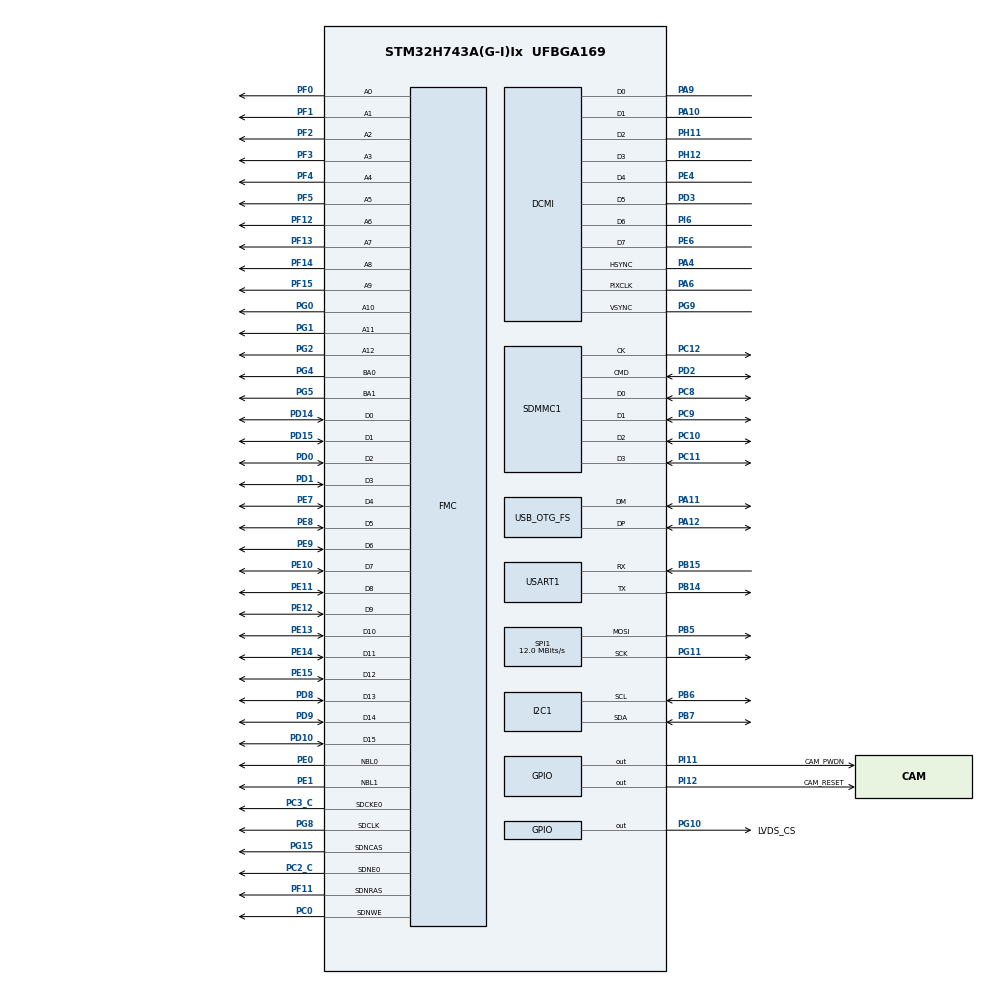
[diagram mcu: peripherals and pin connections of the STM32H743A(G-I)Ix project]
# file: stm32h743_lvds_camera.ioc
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CORTEX_M7.default_mode_Activation=1
DCMI.JPEGMode=DCMI_JPEG_ENABLE
DCMI.PCKPolarity=DCMI_PCKPOLARITY_RISING
DCMI.VSPolarity=DCMI_VSPOLARITY_HIGH
Dma.DCMI.0.Direction=DMA_PERIPH_TO_MEMORY
Dma.DCMI.0.EventEnable=DISABLE
Dma.DCMI.0.FIFOMode=DMA_FIFOMODE_ENABLE
Dma.DCMI.0.FIFOThreshold=DMA_FIFO_THRESHOLD_FULL
Dma.DCMI.0.Instance=DMA1_Stream0
Dma.DCMI.0.MemBurst=DMA_MBURST_SINGLE
Dma.DCMI.0.MemDataAlignment=DMA_MDATAALIGN_WORD
Dma.DCMI.0.MemInc=DMA_MINC_ENABLE
Dma.DCMI.0.Mode=DMA_NORMAL
Dma.DCMI.0.PeriphBurst=DMA_PBURST_SINGLE
Dma.DCMI.0.PeriphDataAlignment=DMA_PDATAALIGN_WORD
Dma.DCMI.0.PeriphInc=DMA_PINC_DISABLE
Dma.DCMI.0.Polarity=HAL_DMAMUX_REQ_GEN_RISING
Dma.DCMI.0.Priority=DMA_PRIORITY_VERY_HIGH
Dma.DCMI.0.RequestNumber=1
Dma.DCMI.0.SignalID=NONE
Dma.DCMI.0.SyncEnable=DISABLE
Dma.DCMI.0.SyncPolarity=HAL_DMAMUX_SYNC_NO_EVENT
Dma.DCMI.0.SyncRequestNumber=1
Dma.DCMI.0.SyncSignalID=NONE
Dma.Request0=DCMI
FMC.CASLatency1=FMC_SDRAM_CAS_LATENCY_3
FMC.ColumnBitsNumber1=FMC_SDRAM_COLUMN_BITS_NUM_9
FMC.ExitSelfRefreshDelay1=8
FMC.LoadToActiveDelay1=2
FMC.RCDDelay1=3
FMC.RPDelay1=3
FMC.RPDelay2=3
FMC.ReadBurst1=FMC_SDRAM_RBURST_ENABLE
FMC.ReadBurst2=FMC_SDRAM_RBURST_ENABLE
FMC.ReadPipeDelay1=FMC_SDRAM_RPIPE_DELAY_1
FMC.ReadPipeDelay2=FMC_SDRAM_RPIPE_DELAY_1
FMC.RowCycleDelay1=7
FMC.RowCycleDelay2=7
FMC.SDClockPeriod1=FMC_SDRAM_CLOCK_PERIOD_2
FMC.SDClockPeriod2=FMC_SDRAM_CLOCK_PERIOD_2
FMC.SelfRefreshTime1=5
FMC.WriteRecoveryTime1=2
I2C1.Timing=0x307075B1
Mcu.Family=STM32H7
Mcu.Name=STM32H743A(G-I)Ix
Mcu.Package=UFBGA169
NVIC.DCMI_IRQn=true\:0\:0\:false\:false\:true\:true\:true\:true
NVIC.DMA1_Stream0_IRQn=true\:0\:0\:false\:false\:true\:false\:true\:true
NVIC.PriorityGroup=NVIC_PRIORITYGROUP_4
PA10.GPIO_Speed=GPIO_SPEED_FREQ_VERY_HIGH
PA10.Mode=Slave_8_bits_External_Synchro
PA10.Signal=DCMI_D1
PA11.Mode=Device_Only
PA11.Signal=USB_OTG_FS_DM
PA12.Mode=Device_Only
PA12.Signal=USB_OTG_FS_DP
PA4.Mode=Slave_8_bits_External_Synchro
PA4.Signal=DCMI_HSYNC
PA6.GPIO_Speed=GPIO_SPEED_FREQ_VERY_HIGH
PA6.Mode=Slave_8_bits_External_Synchro
PA6.Signal=DCMI_PIXCLK
PA9.GPIO_Speed=GPIO_SPEED_FREQ_VERY_HIGH
PA9.Mode=Slave_8_bits_External_Synchro
PA9.Signal=DCMI_D0
PB14.Mode=Asynchronous
PB14.Signal=USART1_TX
PB15.Mode=Asynchronous
PB15.Signal=USART1_RX
PB5.Mode=TX_Only_Simplex_Unidirect_Master
PB5.Signal=SPI1_MOSI
PB6.Mode=I2C
PB6.Signal=I2C1_SCL
PB7.Mode=I2C
PB7.Signal=I2C1_SDA
PC0.Signal=FMC_SDNWE
PC10.Mode=SD_4_bits_Wide_bus
PC10.Signal=SDMMC1_D2
PC11.Mode=SD_4_bits_Wide_bus
PC11.Signal=SDMMC1_D3
PC12.Mode=SD_4_bits_Wide_bus
PC12.Signal=SDMMC1_CK
PC2_C.Mode=SdramChipSelect1_1
PC2_C.Signal=FMC_SDNE0
PC3_C.Mode=SdramChipSelect1_1
PC3_C.Signal=FMC_SDCKE0
PC8.Mode=SD_4_bits_Wide_bus
PC8.Signal=SDMMC1_D0
PC9.Mode=SD_4_bits_Wide_bus
PC9.Signal=SDMMC1_D1
PD0.Signal=FMC_D2_DA2
PD1.Signal=FMC_D3_DA3
PD10.Signal=FMC_D15_DA15
PD14.Signal=FMC_D0_DA0
PD15.Signal=FMC_D1_DA1
PD2.Mode=SD_4_bits_Wide_bus
PD2.Signal=SDMMC1_CMD
PD3.GPIO_Speed=GPIO_SPEED_FREQ_VERY_HIGH
PD3.Mode=Slave_8_bits_External_Synchro
PD3.Signal=DCMI_D5
PD8.Signal=FMC_D13_DA13
PD9.Signal=FMC_D14_DA14
PE0.Signal=FMC_NBL0
PE1.Signal=FMC_NBL1
PE10.Signal=FMC_D7_DA7
PE11.Signal=FMC_D8_DA8
PE12.Signal=FMC_D9_DA9
PE13.Signal=FMC_D10_DA10
PE14.Signal=FMC_D11_DA11
PE15.Signal=FMC_D12_DA12
PE4.GPIO_Speed=GPIO_SPEED_FREQ_VERY_HIGH
PE4.Mode=Slave_8_bits_External_Synchro
PE4.Signal=DCMI_D4
PE6.GPIO_Speed=GPIO_SPEED_FREQ_VERY_HIGH
PE6.Mode=Slave_8_bits_External_Synchro
PE6.Signal=DCMI_D7
PE7.Signal=FMC_D4_DA4
PE8.Signal=FMC_D5_DA5
PE9.Signal=FMC_D6_DA6
PF0.Signal=FMC_A0
PF1.Signal=FMC_A1
PF11.Signal=FMC_SDNRAS
PF12.Signal=FMC_A6
PF13.Signal=FMC_A7
PF14.Signal=FMC_A8
PF15.Signal=FMC_A9
PF2.Signal=FMC_A2
PF3.Signal=FMC_A3
PF4.Signal=FMC_A4
PF5.Signal=FMC_A5
PG0.Signal=FMC_A10
PG1.Signal=FMC_A11
PG10.GPIO_Label=LVDS_CS
PG10.GPIO_Speed=GPIO_SPEED_FREQ_VERY_HIGH
PG10.PinState=GPIO_PIN_SET
PG10.Signal=GPIO_Output
PG11.Mode=TX_Only_Simplex_Unidirect_Master
PG11.Signal=SPI1_SCK
PG15.Signal=FMC_SDNCAS
PG2.Signal=FMC_A12
PG4.Signal=FMC_A14_BA0
PG5.Signal=FMC_A15_BA1
PG8.Signal=FMC_SDCLK
PG9.Mode=Slave_8_bits_External_Synchro
PG9.Signal=DCMI_VSYNC
PH0-OSC_IN\ (PH0).Mode=HSE-External-Oscillator
PH0-OSC_IN\ (PH0).Signal=RCC_OSC_IN
PH1-OSC_OUT\ (PH1).Mode=HSE-External-Oscillator
PH1-OSC_OUT\ (PH1).Signal=RCC_OSC_OUT
PH11.GPIO_Speed=GPIO_SPEED_FREQ_VERY_HIGH
PH11.Mode=Slave_8_bits_External_Synchro
PH11.Signal=DCMI_D2
PH12.GPIO_Speed=GPIO_SPEED_FREQ_VERY_HIGH
PH12.Mode=Slave_8_bits_External_Synchro
PH12.Signal=DCMI_D3
PI11.GPIO_Label=CAM_PWDN
PI11.Signal=GPIO_Output
PI12.GPIO_Label=CAM_RESET
PI12.PinState=GPIO_PIN_SET
PI12.Signal=GPIO_Output
PI6.GPIO_Speed=GPIO_SPEED_FREQ_VERY_HIGH
PI6.Mode=Slave_8_bits_External_Synchro
PI6.Signal=DCMI_D6
ProjectManager.HeapSize=0x200
ProjectManager.StackSize=0x400
ProjectManager.TargetToolchain=MDK-ARM V5.32
RCC.ADCFreq_Value=50390625
RCC.APB1Freq_Value=120000000
RCC.APB2Freq_Value=120000000
RCC.APB3Freq_Value=120000000
RCC.APB4Freq_Value=120000000
RCC.CortexFreq_Value=240000000
RCC.DIVM1=5
RCC.DIVN1=96
RCC.DIVQ1=5
RCC.HCLKFreq_Value=120000000
RCC.HPRE=RCC_HCLK_DIV2
RCC.PLLFRACN=0
RCC.PLLSourceVirtual=RCC_PLLSOURCE_HSE
RCC.SYSCLKFreq_VALUE=240000000
RCC.SYSCLKSource=RCC_SYSCLKSOURCE_PLLCLK
RCC.USBCLockSelection=RCC_USBCLKSOURCE_HSI48
RCC.USBFreq_Value=48000000
SDMMC1.HardwareFlowControl=SDMMC_HARDWARE_FLOW_CONTROL_ENABLE
SH.FMC_A0.0=FMC_A0,13b-sda1
SH.FMC_A1.0=FMC_A1,13b-sda1
SH.FMC_A10.0=FMC_A10,13b-sda1
SH.FMC_A11.0=FMC_A11,13b-sda1
SH.FMC_A12.0=FMC_A12,13b-sda1
SH.FMC_A14_BA0.0=FMC_BA0,FourSdramBanks1
SH.FMC_A15_BA1.0=FMC_BA1,FourSdramBanks1
SH.FMC_A2.0=FMC_A2,13b-sda1
SH.FMC_A3.0=FMC_A3,13b-sda1
SH.FMC_A4.0=FMC_A4,13b-sda1
SH.FMC_A5.0=FMC_A5,13b-sda1
SH.FMC_A6.0=FMC_A6,13b-sda1
SH.FMC_A7.0=FMC_A7,13b-sda1
SH.FMC_A8.0=FMC_A8,13b-sda1
SH.FMC_A9.0=FMC_A9,13b-sda1
SH.FMC_D0_DA0.0=FMC_D0,sd-16b-d1
SH.FMC_D10_DA10.0=FMC_D10,sd-16b-d1
SH.FMC_D11_DA11.0=FMC_D11,sd-16b-d1
SH.FMC_D12_DA12.0=FMC_D12,sd-16b-d1
SH.FMC_D13_DA13.0=FMC_D13,sd-16b-d1
SH.FMC_D14_DA14.0=FMC_D14,sd-16b-d1
SH.FMC_D15_DA15.0=FMC_D15,sd-16b-d1
SH.FMC_D1_DA1.0=FMC_D1,sd-16b-d1
SH.FMC_D2_DA2.0=FMC_D2,sd-16b-d1
SH.FMC_D3_DA3.0=FMC_D3,sd-16b-d1
SH.FMC_D4_DA4.0=FMC_D4,sd-16b-d1
SH.FMC_D5_DA5.0=FMC_D5,sd-16b-d1
SH.FMC_D6_DA6.0=FMC_D6,sd-16b-d1
SH.FMC_D7_DA7.0=FMC_D7,sd-16b-d1
SH.FMC_D8_DA8.0=FMC_D8,sd-16b-d1
SH.FMC_D9_DA9.0=FMC_D9,sd-16b-d1
SH.FMC_NBL0.0=FMC_NBL0,Sd2ByteEnable1
SH.FMC_NBL1.0=FMC_NBL1,Sd2ByteEnable1
SH.FMC_SDCLK.0=FMC_SDCLK,13b-sda1
SH.FMC_SDNCAS.0=FMC_SDNCAS,13b-sda1
SH.FMC_SDNRAS.0=FMC_SDNRAS,13b-sda1
SH.FMC_SDNWE.0=FMC_SDNWE,13b-sda1
SPI1.BaudRatePrescaler=SPI_BAUDRATEPRESCALER_8
SPI1.CLKPhase=SPI_PHASE_2EDGE
SPI1.CalculateBaudRate=12.0 MBits/s
SPI1.DataSize=SPI_DATASIZE_8BIT
SPI1.Direction=SPI_DIRECTION_2LINES_TXONLY
SPI1.Mode=SPI_MODE_MASTER
SPI1.NSSPMode=SPI_NSS_PULSE_DISABLE
SPI1.VirtualType=VM_MASTER
USART1.VirtualMode-Asynchronous=VM_ASYNC
USB_OTG_FS.VirtualMode=Device_Only
VP_FATFS_VS_Generic.Mode=User_defined
VP_MEMORYMAP_VS_MEMORYMAP.Mode=CurAppReg
board=custom

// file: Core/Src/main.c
/* USER CODE BEGIN Header */
/**
  ******************************************************************************
  * @file           : main.c
  * @brief          : Main program body
  ******************************************************************************
  * @attention
  *
  * Copyright (c) 2026 STMicroelectronics.
  * All rights reserved.
  *
  * This software is licensed under terms that can be found in the LICENSE file
  * in the root directory of this software component.
  * If no LICENSE file comes with this software, it is provided AS-IS.
  *
  ******************************************************************************
  */
/* USER CODE END Header */
#include "main.h"
#include "dcmi.h"
#include "dma.h"
#include "fatfs.h"
#include "i2c.h"
#include "sdmmc.h"
#include "spi.h"
#include "usart.h"
#include "usb_otg.h"
#include "gpio.h"
#include "fmc.h"

/* USER CODE BEGIN Includes */
#include "app/app_camera.h"
#include "services/storage.h"
#include "services/remote_control.h"
#include "services/uart_video_tx.h"
#include "services/uart_image_tx.h"

/* USER CODE END Includes */

void SystemClock_Config(void);
/* USER CODE BEGIN PFP */
static void MPU_Config(void);
/* USER CODE END PFP */

int main(void)
{

  /* USER CODE BEGIN 1 */
  MPU_Config();  /* before HAL_Init(): MPU must cover SDRAM first */

  /* USER CODE END 1 */

  /* MCU Configuration--------------------------------------------------------*/

  /* Reset of all peripherals, Initializes the Flash interface and the Systick. */
  HAL_Init();

  /* Configure the system clock */
  SystemClock_Config();

  /* Initialize all configured peripherals */
  MX_GPIO_Init();
  MX_DMA_Init();
  MX_FMC_Init();
  MX_DCMI_Init();
  MX_I2C1_Init();
  MX_SDMMC1_SD_Init();
  MX_SPI1_Init();
  MX_USB_OTG_FS_PCD_Init();
  MX_FATFS_Init();
  MX_USART1_UART_Init();
  /* USER CODE BEGIN 2 */
  /* SD 首次验证：只挂载和读取容量，不会改动卡内任何文件。 */
  (void)Storage_Mount();
  App_CameraInit();

  /* USART1 remote control: interrupt reception of command frames. */
  RemoteControl_Init();
  UARTVideoTx_Init();
  UARTImageTx_Init();

  /* USER CODE END 2 */

  /* Infinite loop */
  /* USER CODE BEGIN WHILE */
  while (1)
  {
    RemoteControl_Process();
    Storage_Process();
    App_CameraProcess();
    UARTVideoTx_Process();
    UARTImageTx_Process();
    /* USER CODE END WHILE */

  }
}

void SystemClock_Config(void)
{
  RCC_OscInitTypeDef RCC_OscInitStruct = {0};
  RCC_ClkInitTypeDef RCC_ClkInitStruct = {0};

  /** Supply configuration update enable
  */
  HAL_PWREx_ConfigSupply(PWR_LDO_SUPPLY);

  /** Configure the main internal regulator output voltage
  */
  __HAL_PWR_VOLTAGESCALING_CONFIG(PWR_REGULATOR_VOLTAGE_SCALE2);

  while(!__HAL_PWR_GET_FLAG(PWR_FLAG_VOSRDY)) {}

  /** Initializes the RCC Oscillators according to the specified parameters
  * in the RCC_OscInitTypeDef structure.
  */
  RCC_OscInitStruct.OscillatorType = RCC_OSCILLATORTYPE_HSI48|RCC_OSCILLATORTYPE_HSE;
  RCC_OscInitStruct.HSEState = RCC_HSE_ON;
  RCC_OscInitStruct.HSI48State = RCC_HSI48_ON;
  RCC_OscInitStruct.PLL.PLLState = RCC_PLL_ON;
  RCC_OscInitStruct.PLL.PLLSource = RCC_PLLSOURCE_HSE;
  RCC_OscInitStruct.PLL.PLLM = 5;
  RCC_OscInitStruct.PLL.PLLN = 96;
  RCC_OscInitStruct.PLL.PLLP = 2;
  RCC_OscInitStruct.PLL.PLLQ = 5;
  RCC_OscInitStruct.PLL.PLLR = 2;
  RCC_OscInitStruct.PLL.PLLRGE = RCC_PLL1VCIRANGE_2;
  RCC_OscInitStruct.PLL.PLLVCOSEL = RCC_PLL1VCOWIDE;
  RCC_OscInitStruct.PLL.PLLFRACN = 0;
  if (HAL_RCC_OscConfig(&RCC_OscInitStruct) != HAL_OK)
  {
    Error_Handler();
  }

  /** Initializes the CPU, AHB and APB buses clocks
  */
  RCC_ClkInitStruct.ClockType = RCC_CLOCKTYPE_HCLK|RCC_CLOCKTYPE_SYSCLK
                              |RCC_CLOCKTYPE_PCLK1|RCC_CLOCKTYPE_PCLK2
                              |RCC_CLOCKTYPE_D3PCLK1|RCC_CLOCKTYPE_D1PCLK1;
  RCC_ClkInitStruct.SYSCLKSource = RCC_SYSCLKSOURCE_PLLCLK;
  RCC_ClkInitStruct.SYSCLKDivider = RCC_SYSCLK_DIV1;
  RCC_ClkInitStruct.AHBCLKDivider = RCC_HCLK_DIV2;
  RCC_ClkInitStruct.APB3CLKDivider = RCC_APB3_DIV1;
  RCC_ClkInitStruct.APB1CLKDivider = RCC_APB1_DIV1;
  RCC_ClkInitStruct.APB2CLKDivider = RCC_APB2_DIV1;
  RCC_ClkInitStruct.APB4CLKDivider = RCC_APB4_DIV1;

  if (HAL_RCC_ClockConfig(&RCC_ClkInitStruct, FLASH_LATENCY_2) != HAL_OK)
  {
    Error_Handler();
  }
}

/* USER CODE BEGIN 4 */
/* Hand-maintained MPU setup (the .ioc holds no MPU region entries):
 * keep it inside this USER CODE block so regeneration preserves it. */
 /* MPU Configuration */

void MPU_Config(void)
{
  MPU_Region_InitTypeDef MPU_InitStruct = {0};

  /* Disables the MPU */
  HAL_MPU_Disable();

  /** Initializes and configures the Region and the memory to be protected
  */
  MPU_InitStruct.Enable = MPU_REGION_ENABLE;
  MPU_InitStruct.Number = MPU_REGION_NUMBER0;
  MPU_InitStruct.BaseAddress = 0x0;
  MPU_InitStruct.Size = MPU_REGION_SIZE_4GB;
  MPU_InitStruct.SubRegionDisable = 0x87;
  MPU_InitStruct.TypeExtField = MPU_TEX_LEVEL0;
  MPU_InitStruct.AccessPermission = MPU_REGION_NO_ACCESS;
  MPU_InitStruct.DisableExec = MPU_INSTRUCTION_ACCESS_DISABLE;
  MPU_InitStruct.IsShareable = MPU_ACCESS_SHAREABLE;
  MPU_InitStruct.IsCacheable = MPU_ACCESS_NOT_CACHEABLE;
  MPU_InitStruct.IsBufferable = MPU_ACCESS_NOT_BUFFERABLE;

  HAL_MPU_ConfigRegion(&MPU_InitStruct);

  /* SDRAM frame buffer: DCMI DMA and CPU/LVDS/SD tasks must both access it. */
  MPU_InitStruct.Enable = MPU_REGION_ENABLE;
  MPU_InitStruct.Number = MPU_REGION_NUMBER1;
  MPU_InitStruct.BaseAddress = 0xC0000000U;
  MPU_InitStruct.Size = MPU_REGION_SIZE_32MB;
  MPU_InitStruct.SubRegionDisable = 0x00U;
  /* TEX=1 + C=0 + B=0：Normal 非缓存内存。TEX=0+C=0+B=0 是 Strongly-Ordered，
   * 其非对齐访问会触发 UNALIGNED HardFault（FatFs 直通写 SD 时指针可能 2 字节对齐）。 */
  MPU_InitStruct.TypeExtField = MPU_TEX_LEVEL1;
  MPU_InitStruct.AccessPermission = MPU_REGION_FULL_ACCESS;
  MPU_InitStruct.DisableExec = MPU_INSTRUCTION_ACCESS_DISABLE;
  MPU_InitStruct.IsShareable = MPU_ACCESS_SHAREABLE;
  MPU_InitStruct.IsCacheable = MPU_ACCESS_NOT_CACHEABLE;
  MPU_InitStruct.IsBufferable = MPU_ACCESS_NOT_BUFFERABLE;
  HAL_MPU_ConfigRegion(&MPU_InitStruct);
  /* Enables the MPU */
  HAL_MPU_Enable(MPU_PRIVILEGED_DEFAULT);

}

/* USER CODE END 4 */

void Error_Handler(void)
{
  __disable_irq();
  while (1)
  {
  }
}
